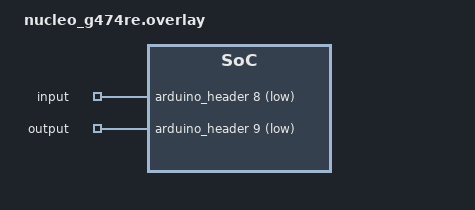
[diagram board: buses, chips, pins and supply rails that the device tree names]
/*
 * SPDX-FileCopyrightText: Copyright (C) Frickly Systems GmbH
 * SPDX-FileCopyrightText: Copyright (C) MBition GmbH
 *
 * SPDX-License-Identifier: Apache-2.0
 */

/ {

    aliases {
        input = &input;
        output = &output;
    };

    keys: keys {
        compatible = "gpio-keys";

        input: input {
            gpios = <&arduino_header 8 (GPIO_ACTIVE_LOW|GPIO_PULL_UP)>; // D2
        };

        output: output {
            gpios = <&arduino_header 9 GPIO_ACTIVE_LOW>; // D3;
        };
    };

};
